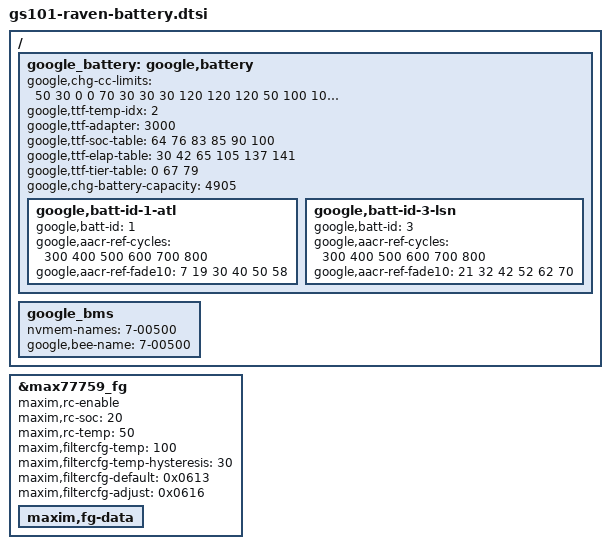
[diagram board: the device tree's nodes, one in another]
// SPDX-License-Identifier: GPL-2.0-only
/*
 * Battery device tree entries specific to raven
 *
 * Copyright 2021 Google,LLC
 *
 */

&google_battery {
	google,chg-battery-capacity = <4905>;
};

/ {
	fragment@battery {
		target-path = "/";
		__overlay__ {
			google_battery: google,battery {
				google,chg-cc-limits = <
				50   30   0    0 		/* 10c 	2A*/
               	70   30   30   30 		/* 20c 	3.5A*/	
               	120  120  120  50		/* 38c 	6A*/	
              	100  100  100  50		/* 40c  5A*/	
              	80   80   80   50		/* 43c 	4A*/	
               	50   50   0    0		/* 45c 	2A*/	
               	30   0    0    0		/* 50c	1A*/	
				>;
				
				google,ttf-temp-idx= <2>;
				google,ttf-adapter = <3000>;
				google,ttf-soc-table =  <64 76 83 85  90  100>;
				google,ttf-elap-table = <30 42 65 105 137 141>;
				google,ttf-tier-table = <0 67 79>;

				google,batt-id-1-atl {
					google,batt-id = <1>;
					google,aacr-ref-cycles = <300 400 500 600 700 800>;
					google,aacr-ref-fade10 = <7   19  30  40  50  58>;
				};

				google,batt-id-3-lsn {
					google,batt-id = <3>;
					google,aacr-ref-cycles = <300 400 500 600 700 800>;
					google,aacr-ref-fade10 = <21  32  42  52  62  70>;
				};
			};

			google_bms {
				nvmem-names = "7-00500";
				/* pack eeprom is available only with P20+ batteries */
				google,bee-name = "7-00500";
			};
		};
	};
};

&max77759_fg {
	maxim,rc-enable;
	maxim,rc-soc = <20>;
	maxim,rc-temp = <50>;
	maxim,filtercfg-temp = <100>;
	maxim,filtercfg-temp-hysteresis = <30>;
	maxim,filtercfg-default = /bits/ 16 <0x0613>;
	maxim,filtercfg-adjust = /bits/ 16 <0x0616>;

	maxim,fg-data {
		#include "gs101-raven-battery-data.dtsi"
	};
};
